# PIC32CZ4010CA90208 register map
Vendor: Microchip Technology; Series: PIC32CZCA90; File version: 0
CPU: CM7 r1p1, little endian, MPU, FPU, double-precision FPU, I-cache, D-cache, ITCM, DTCM, 3 interrupt priority bits, 222 interrupts
Registers are 32-bit, read-write, reset 0x0 unless marked. A register's access mark holds for its fields unless they carry their own. Offsets are from the block's base; [hi:lo] are bit positions; {n}, {i} and the like mark numbered series; 'fields as' and 'values as' point back to an identical list.

## HSM — Hardware Security Module
Base 0x4F018000
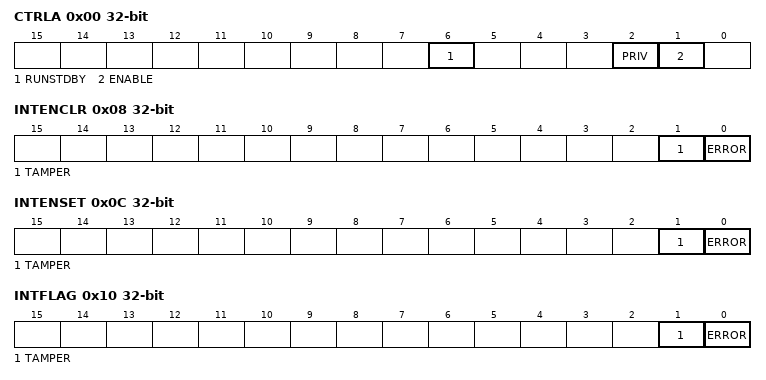
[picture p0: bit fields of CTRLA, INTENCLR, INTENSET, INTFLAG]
0x00 CTRLA — CONTROL REGISTER A
  [6] RUNSTDBY — Run In Standby bit
  [2] PRIV — Privileged Access Only bit
  [1] ENABLE — Clock Enable bit
0x04 CTRLB — CONTROL REGISTER B
  [0] CANCEL — Cancel Command
0x08 INTENCLR write-1-clears — INTERRUPT ENABLE CLEAR REGISTER
  [1] TAMPER — Tamper Interrupt Enable
  [0] ERROR — Error Interrupt Enable
0x0C INTENSET write-1-sets — INTERRUPT ENABLE SET
  fields as INTENCLR
0x10 INTFLAG write-1-clears — INTERRUPT FLAG
  [1] TAMPER — Tamper Interrupt Flag
  [0] ERROR — Error Interrupt Flag
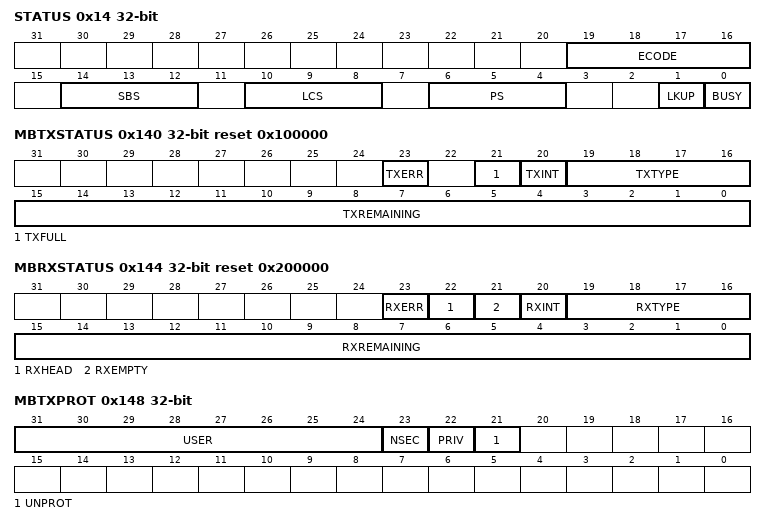
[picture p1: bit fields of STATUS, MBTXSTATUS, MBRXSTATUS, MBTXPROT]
0x14 STATUS
  [19:16] ECODE — ERROR CODE
  [14:12] SBS — SECURE BOOT STATE
  [10:8] LCS — LIFECYCLE STATE
  [6:4] PS — PROCESSING STATE
  [1] LKUP — HSM CPU LOCKUP
  [0] BUSY — HSM CPU BUSY
{0x100+4i} MBFIFO[{i}] (i=0..15) read-modifies — MAILBOX FIFO
  [31:0] MBFIFO
0x140 MBTXSTATUS reset 0x100000 — MAILBOX TRANSMIT STATUS
  [23] TXERR — TRANSMIT ERROR
  [21] TXFULL — TRANSMIT FIFO FULL
  [20] TXINT — TRANSMIT FIFO INTERRUPT FLAG
  [19:16] TXTYPE — TRANSMIT MESSAGE HEADER TYPE
  [15:0] TXREMAINING — TRANSMIT BYTES REMAINING
0x144 MBRXSTATUS reset 0x200000 — MAILBOX RECEIVE STATUS
  [23] RXERR — RECEIVE ERROR
  [22] RXHEAD — Receive Header Next Word bit
  [21] RXEMPTY — RECEIVE FIFO FULL
  [20] RXINT — RECEIVE FIFO INTERRUPT FLAG
  [19:16] RXTYPE — RECEIVE MESSAGE HEADER TYPE
  [15:0] RXREMAINING — RECEIVE BYTES REMAINING
0x148 MBTXPROT — MAILBOX TX PROTECTION
  [31:24] USER — USER SIDEBAND
  [23] NSEC — MAILBOX MESSAGE NON-SECURE ACCESS
  [22] PRIV — MAILBOX MESSAGE PRIVILEDGED ACCESS
  [21] UNPROT — MAILBOX UNPROTECTED
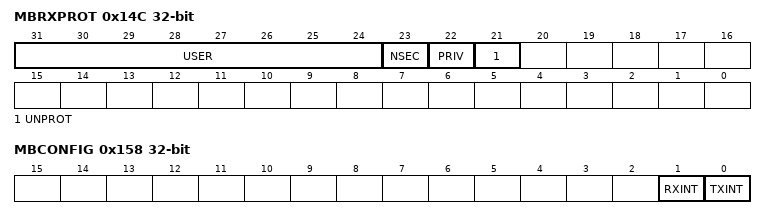
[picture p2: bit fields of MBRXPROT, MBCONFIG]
0x14C MBRXPROT — MAILBOX RX PROTECTION
  fields as MBTXPROT
0x150 MBTXHEAD read-modifies — MAILBOX TRANSMIT HEADER
  [31:0] TXHEAD — MAILBOX TRANSMIT HEADER REGISTER
0x154 MBRXHEAD read-modifies — MAILBOX RECEIVE HEADER
  [31:0] RXHEAD — MAILBOX RECEIVE HEADER REGISTER
0x158 MBCONFIG — MAILBOX CONFIGURATION
  [1] RXINT — MAILBOX RECEIVE INTERRUPT ENABLE
  [0] TXINT — MAILBOX TRANSMIT INTERRUPT ENABLE

## ITM — Instrumentation Trace Macrocell
Base 0xE0041000; alternate view of ETM
{0x0+4i} PORT_BYTE_MODE[{i}] (i=0..31) wo — ITM Stimulus Port Registers
  [7:0] PORT
{0x0+4i} PORT_HWORD_MODE[{i}] (i=0..31) wo (alternate view of PORT_BYTE_MODE[{i}]) — ITM Stimulus Port Registers
  [15:0] PORT
{0x0+4i} PORT_WORD_MODE[{i}] (i=0..31) wo (alternate view of PORT_BYTE_MODE[{i}]) — ITM Stimulus Port Registers
  [31:0] PORT
0xE00 TER — ITM Trace Enable Register
0xE40 TPR — ITM Trace Privilege Register
  [3:0] PRIVMASK
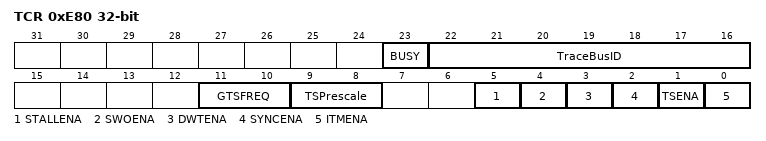
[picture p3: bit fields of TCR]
0xE80 TCR — ITM Trace Control Register
  [23] BUSY, [22:16] TraceBusID, [11:10] GTSFREQ, [9:8] TSPrescale, [5] STALLENA, [4] SWOENA, [3] DWTENA, [2] SYNCENA, [1] TSENA, [0] ITMENA
0xEF8 IWR wo — ITM Integration Write Register
  [0] ATVALIDM
0xEFC IRR ro — ITM Integration Read Register
  [0] ATREADYM

## MCLK — Main Clock
Base 0x44052000
0x00 INTENCLR write-1-clears — Interrupt Enable Clear
  [0] CKRDY — Clock Ready Interrupt Enable
0x04 INTENSET write-1-sets — Interrupt Enable Set
  [0] CKRDY — Clock Ready Interrupt Enable
0x08 INTFLAG reset 0x1 write-1-clears — Interrupt Flag Status and Clear
  [0] CKRDY — Clock Ready
{0xC+4i} CLKDIV[{i}] (i=0..1) — Clock Divider Control
  [7:0] DIV — Clock Domain Division Factor
    1=Divide by 1; 2=Divide by 2; 4=Divide by 4; 8=Divide by 8; 16=Divide by 16; 32=Divide by 32; 64=Divide by 64; 128=Divide by 128
{0x3C+4i} CLKMSK[{i}] (i=0..8) — Peripheral Clock Enable Mask
  [31:0] MASK

## MCRAMC — Multi-Channel RAM Controller
Base 0x44822000
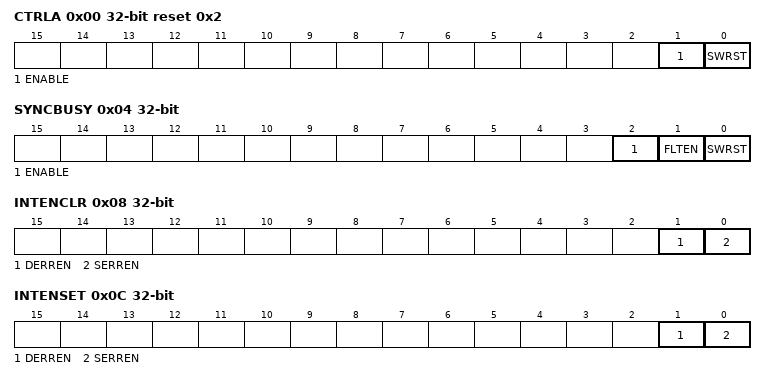
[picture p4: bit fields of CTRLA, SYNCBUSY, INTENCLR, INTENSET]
0x00 CTRLA reset 0x2 — Control Enable A Register
  [1] ENABLE — ECC Decoder Enable
    0=ECC decoding is disabled; 1=ECC decoding is enabled
  [0] SWRST — Software Reset
    0=No effect; 1=Reset the MCRAMC. A software-triggered hardware reset of the MCRAMC user interface is performed.
0x04 SYNCBUSY ro
  [2] ENABLE — ECC Decoder Enable busy bit
  [1] FLTEN — Fault Injection Enabled busy bit
  [0] SWRST — Software reset busy bit
0x08 INTENCLR — Interrupt Enable Clear Register
  [1] DERREN — Double Bit Error Interrupt Enable, Clear
  [0] SERREN — Single Bit Error Interrupt Enable, Clear
0x0C INTENSET — Interrupt Enable Set Register
  [1] DERREN — Double Bit Error Interrupt Enable, Set
  [0] SERREN — Single Bit Error Interrupt Enable, Set
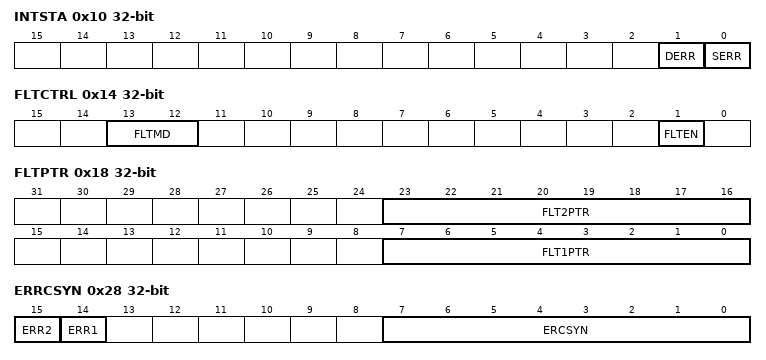
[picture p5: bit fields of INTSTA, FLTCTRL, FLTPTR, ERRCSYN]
0x10 INTSTA — Interrupt Status Register
  [1] DERR — Double Bit Error
  [0] SERR — Single Bit Error
0x14 FLTCTRL — Fault Injection Control Register
  [13:12] FLTMD — Fault Injection Mode
  [1] FLTEN — Fault Injection Enabled
    0=Disables fault injection; 1=Enables fault injection at FLTADR address offset as selected by FLTMD and FLTxPTR
0x18 FLTPTR — Fault Injection Pointer Register
  [23:16] FLT2PTR — Double Fault Injection Bit Pointer
  [7:0] FLT1PTR — Single Fault Injection Bit Pointer
0x1C FLTADR — Fault Injection Address Register
  [23:0] FLTADR — Fault Address Offset
0x20 ERRCADR ro — Error Capture Address Register
  [23:0] ERCADR — ECC SECDED Error Capture Address
0x24 ERRCPAR ro — Error Capture Parity Register
  [7:0] ERCPAR — ECC SECDED Error Capture Parity
0x28 ERRCSYN ro — Error Capture Syndrome Register
  [15] ERR2 — ECC Double Bit Error
    0=Not a Double bit error; 1=Double bit error
  [14] ERR1 — ECC Single Bit Error
  [7:0] ERCSYN — ECC SECDED Error Capture Syndrome
    0=Not a Single bit error; 1=Single bit error

## Notices in the file
Copyright (c) 2026 Microchip Technology Inc.
SPDX-License-Identifier: Apache-2.0
Licensed under the Apache License, Version 2.0 (the "License");
you may not use this file except in compliance with the License.
You may obtain a copy of the License at
http://www.apache.org/licenses/LICENSE-2.0
Unless required by applicable law or agreed to in writing, software
distributed under the License is distributed on an "AS IS" BASIS,
WITHOUT WARRANTIES OR CONDITIONS OF ANY KIND, either express or implied.
See the License for the specific language governing permissions and
limitations under the License.
